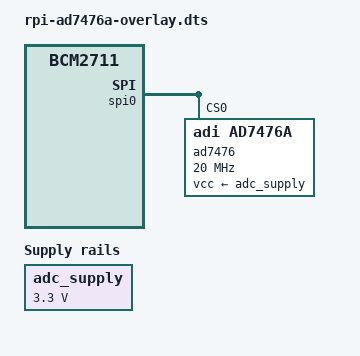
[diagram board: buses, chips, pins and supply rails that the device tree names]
/dts-v1/;
/plugin/;

/ {
	compatible = "brcm,bcm2835", "brcm,bcm2708", "brcm,bcm2709", "brcm,bcm2711";

	fragment@0 {
		target-path = "/";
		__overlay__ {
		       adc_supply: fixedregulator {
               compatible = "regulator-fixed";
               regulator-name = "fixed-supply";
               regulator-min-microvolt = <3300000>;
               regulator-max-microvolt = <3300000>;
			   regulator-boot-on;
       		};
		};
	};

	fragment@1 {
		target = <&spi0>;
		__overlay__ {
			#address-cells = <0>;
			#size-cells = <0>;
			status = "okay";

			ad7476@0 {
				compatible = "adi,ad7476a";
				reg = <0>;
				spi-max-frequency = <20000000>;
				spi-cpha;
				spi-cpol;
				vcc-supply = <&adc_supply>;
               };
		};
	};

	fragment@2 {
		target = <&spidev0>;
		__overlay__ {
			status = "disabled";
		};
	};
};

